# S6E1C1xC register map
Vendor: Cypress; File version: 2.1
CPU: CM0PLUS r0p1, little endian, no MPU, no FPU, 2 interrupt priority bits
Registers are 32-bit, read-write, reset 0x0 unless marked. A register's access mark holds for its fields unless they carry their own. Offsets are from the block's base; [hi:lo] are bit positions; {n}, {i} and the like mark numbered series.

## I2CSLAVE — I2C Slave Wakeup
Base 0x40037980
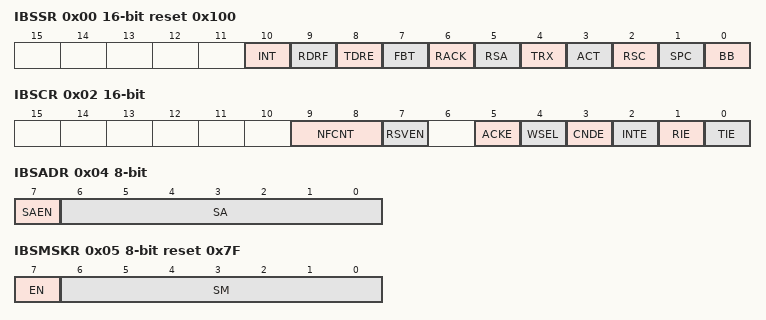
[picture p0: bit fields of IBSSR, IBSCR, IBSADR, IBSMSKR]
0x00 IBSSR 16-bit ro reset 0x100 — I2C Bus Slave Status Register [BHW]
  [10] INT — Status Interrupt Request flag
  [9] RDRF — Reception Interrupt Request flag
  [8] TDRE — Transmission Data Empty flag
  [7] FBT — First Byte flag
  [6] RACK — Acknowledge flag
  [5] RSA — Reserved Address Detection flag
  [4] TRX — Data Direction flag
  [3] ACT — Active flag
  [2] RSC — Re-Start Condition Detection flag
  [1] SPC — Stop Condition Detection flag
  [0] BB — Bus Busy flag
0x02 IBSCR 16-bit — I2C Bus Slave Control Register [BHW]
  [9:8] NFCNT — Noise Filter Control bits
  [7] RSVEN — Reserved Address Enable bit
  [5] ACKE — Acknowledge Enable bit
  [4] WSEL — Wait Select bit
  [3] CNDE — Condition Detection Interrupt Request Enable bit
  [2] INTE — Status Interrupt Request Enable bit
  [1] RIE — Reception Interrupt Request Enable bit
  [0] TIE — Transmission Interrupt Request Enable bit
0x04 IBSADR 8-bit — I2C Bus 7-bit Slave Address Register [BHW]
  [7] SAEN — Slave Address Enable bit
  [6:0] SA — Slave Address Value bit
0x05 IBSMSKR 8-bit reset 0x7F — I2C Bus 7-bit Slave Address Mask Register [BHW]
  [7] EN — Operating Enable bit
  [6:0] SM — Slave Address Mask bit
0x06 IBSDSTUPR 8-bit reset 0xFF — I2C Bus Slave Data Setup Register [BHW]
  [7:0] SETUP — Setup bits
0x08 IBSTDR 8-bit reset 0xFF — I2C Bus Slave Transmission Data Register [BHW]
  [7:0] TDR — Transmission Data bits
0x0C IBSRDR 8-bit ro reset 0xFF — I2C Bus Slave Reception Data Register [BHW]
  [7:0] RDR — Reception Data bis
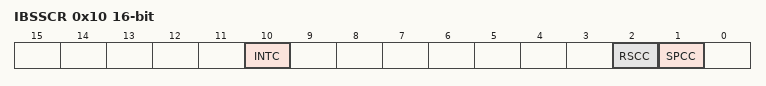
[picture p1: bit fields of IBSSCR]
0x10 IBSSCR 16-bit wo — I2C Bus Slave Status Clear Register [BHW]
  [10] INTC — Status Interrupt Request Flag Clear bit
  [2] RSCC — Re-Start Condition Detection Flag Clear bit
  [1] SPCC — Stop Condition Detection Flag Clear bit
0x14 IBSSSR 16-bit wo — I2C Bus Slave Status Set Register [BHW]
  [8] TDRES — Transmission Data Empty Flag Set bit

## CRC — CRC Registers
Base 0x40039000
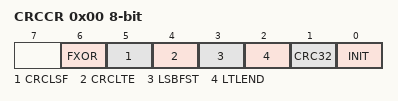
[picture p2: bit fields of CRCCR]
0x00 CRCCR 8-bit — CRC Control Register [BHW]
  [6] FXOR — Final XOR control bit
  [5] CRCLSF — CRC result bit-order setting bit
  [4] CRCLTE — CRC result byte-order setting bit
  [3] LSBFST — Bit-order setting bit
  [2] LTLEND — Byte-order setting bit
  [1] CRC32 — CRC mode selection bit
  [0] INIT — Initialization bit
0x04 CRCINIT reset 0xFFFFFFFF — Initial Value Register [BHW]
  [31:0] D — Initial value bits
0x08 CRCIN — Input Data Register [BHW]
  [31:0] D — Input data bits
0x0C CRCR ro reset 0xFFFFFFFF — CRC Register [BHW]
  [31:0] D — CRC bits

## WC — Watch Counter
Base 0x4003A000
0x00 WCRD 8-bit ro — Watch Counter Read Register [BHW]
  [5:0] CTR — Counter read bits
0x01 WCRL 8-bit — Watch Counter Reload Register [BHW]
  [5:0] RLC — Counter reload value setting bits
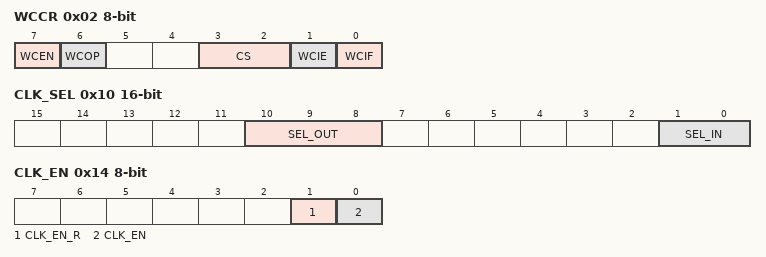
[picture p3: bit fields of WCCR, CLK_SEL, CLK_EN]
0x02 WCCR 8-bit — Watch Counter Control Register [BHW]
  [7] WCEN — Watch counter operation enable bit
  [6] WCOP ro — Watch counter operating state flag
  [3:2] CS — Count clock select bits
  [1] WCIE — Interrupt request enable bit
  [0] WCIF — Interrupt request flag bit
0x10 CLK_SEL 16-bit — Clock Selection Register [BHW]
  [10:8] SEL_OUT — Output clock selection bit
  [1:0] SEL_IN — Input clock selection bit
0x14 CLK_EN 8-bit — Division Clock Enable Register [BHW]
  [1] CLK_EN_R — Division clock enable read bit
  [0] CLK_EN — Division clock enable bit

## LSCRP — Low-speed CR Prescaler Register
Base 0x4003C000
0x00 LCR_PRSLD 8-bit — Low-speed CR Prescaler Control Register [BHW]
  [5:0] LCR_PRSLD — Low-speed CR Prescaler Load

## MFSI2S0 — I2S0 Registers
Base 0x4003CA00
Same registers: MFSI2S1 0x4003CA80
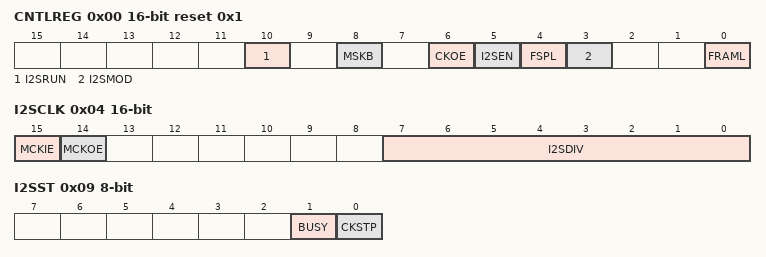
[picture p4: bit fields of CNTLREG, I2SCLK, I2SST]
0x00 CNTLREG 16-bit reset 0x1 — Control Register [HW]
  [10] I2SRUN — I2S clock generate enable bit
  [8] MSKB — Mask bit output bit
  [6] CKOE — I2SCK and I2SWS output enable bit
  [5] I2SEN — I2S mode enable bit
  [4] FSPL — I2SWS polarity set bit
  [3] I2SMOD — I2S mode select bit
  [0] FRAML — Frame length select bit
0x04 I2SCLK 16-bit — I2S Clock Register [HW]
  [15] MCKIE — Main clock input enable bit
  [14] MCKOE — Main clock output enable bit
  [7:0] I2SDIV — I2S clock division set bit
0x08 I2SRST 8-bit wo — I2S Reset Register [B]
  [7:0] I2SRST — I2S software reset bit
0x09 I2SST 8-bit ro — I2S Status Register [B]
  [1] BUSY — Bus busy indication for transmit bit
  [0] CKSTP — Clock stop indication bit

## DSTC — DSTC registers
Base 0x40061000
0x00 DESTP — Descriptor top address Register [BHW]
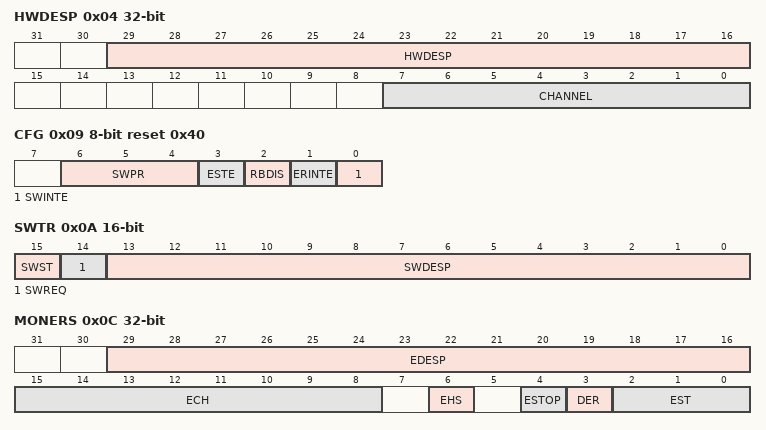
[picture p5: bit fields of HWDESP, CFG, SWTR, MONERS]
0x04 HWDESP — Hardware DES pointer Register [BHW]
  [29:16] HWDESP, [7:0] CHANNEL
0x08 CMD 8-bit reset 0x1 — Command Register [B]
0x09 CFG 8-bit reset 0x40 — Configuration Register [B]
  [6:4] SWPR — Software transfer priority
  [3] ESTE — Error stop enable
  [2] RBDIS — Read skip buffer disable
  [1] ERINTE — Error interrupt enable
  [0] SWINTE — Software interrupt enable
0x0A SWTR 16-bit — Software trigger Register [H]
  [15] SWST ro — Software status
  [14] SWREQ ro — Software request
  [13:0] SWDESP — Software DES pointer
0x0C MONERS — Transfer Error Status Monitor Register [BHW]
  [29:16] EDESP ro — Error DES pointer
  [15:8] ECH ro — Error hardware channel
  [6] EHS ro — Error hardware software
  [4] ESTOP ro — Error stop
  [3] DER ro — Double error
  [2:0] EST ro — Error status
0x10 DREQENB0 — DMA request enable Register 0 [BHW]
0x14 DREQENB1 — DMA request enable Register 1 [BHW]
0x30 HWINT0 — Hardware transfer interrupt Register 0 [BHW]
0x34 HWINT1 — Hardware transfer interrupt Register 1 [BHW]
0x50 HWINTCLR0 — Hardware transfer interrupt clear Register 0 [BHW]
0x54 HWINTCLR1 — Hardware transfer interrupt clear Register 1 [BHW]
0x70 DQMSK0 — DMA request mask Register 0 [BHW]
0x74 DQMSK1 — DMA request mask Register 1 [BHW]
0x90 DQMSKCLR0 — DMA request mask clear Register 0 [BHW]
0x94 DQMSKCLR1 — DMA request mask clear Register 1 [BHW]

## MTB_DWT — Micro Trace Buffer Data Watchpoint and Trace Registers
Base 0xF0001000
0x00 CMP_ADDR_START — MTB_DWT Address Compare Start trace Register [BHW]
  [31:0] ADCMP_STA — MTB_DWT address comparison start trace bits
0x04 CMP_DATA_START — MTB_DWT Data Compare Start trace Register [BHW]
  [31:0] DTCMP_STA — MTB_DWT data comparison start trace bits
0x08 CMP_MASK_START — MTB_DWT Mask Data Compare Start Trace Register [BHW]
  [31:0] MSK_STA — MTB_DWT data compare start trace register mask bits
0x10 CMP_ADDR_STOP — MTB_DWT Address Compare Stop trace Register [BHW]
  [31:0] ADCMP_STO — MTB_DWT address comparison stop trace bits
0x14 CMP_DATA_STOP — MTB_DWT Data Compare Stop trace Register [BHW]
  [31:0] DTCMP_STO — MTB_DWT data comparison stop trace bits
0x18 CMP_MASK_STOP — MTB_DWT Mask Data Compare Stop Trace Register [BHW]
  [31:0] MSK_STO — MTB_DWT data compare stop trace register mask bits
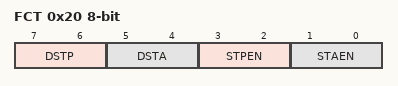
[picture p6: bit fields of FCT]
0x20 FCT 8-bit — MTB_DWT Function Register [BHW]
  [7:6] DSTP — Data size stop bits
  [5:4] DSTA — Data size start bits
  [3:2] STPEN — Enable MTB_DWT stop MTB function bits
  [1:0] STAEN — Enable MTB_DWT start MTB function bits
{0xFC0+4i} PID{i} ro (i=4..7) — Peripheral ID{i} Register [BHW]
  [31:0] PERID — Peripheral ID bits
0xFE0 PID0 ro reset 0x16 — Peripheral ID0 Register [BHW]
  [31:0] PERID — Peripheral ID bits
0xFE4 PID1 ro reset 0x48 — Peripheral ID1 Register [BHW]
  [31:0] PERID — Peripheral ID bits
0xFE8 PID2 ro reset 0x8 — Peripheral ID2 Register [BHW]
  [31:0] PERID — Peripheral ID bits
0xFEC PID3 ro — Peripheral ID3 Register [BHW]
  [31:0] PERID — Peripheral ID bits
0xFF0 CID0 ro reset 0xD — Component ID0 Register [BHW]
  [31:0] CPNTID — Component ID bits
0xFF4 CID1 ro reset 0x90 — Component ID1 Register [BHW]
  [31:0] CPNTID — Component ID bits
0xFF8 CID2 ro reset 0x5 — Component ID2 Register [BHW]
  [31:0] CPNTID — Component ID bits
0xFFC CID3 ro reset 0xB1 — Component ID3 Register [BHW]
  [31:0] CPNTID — Component ID bits

## VIR — Vector Indicate Registers
Base 0xF8000100
{0x0+4i} VIR{i:02} ro (i=0..31) — Vector Indicate Register {i:02} [W]

## Notices in the file
Copyright (C) 2013-2016, Cypress Semiconductor Corporation or a
subsidiary of Cypress Semiconductor Corporation.  All rights reserved.
This software, including source code, documentation and related
materials ("Software"), is owned by Cypress Semiconductor Corporation or
one of its subsidiaries ("Cypress") and is protected by and subject to
worldwide patent protection (United States and foreign), United States
copyright laws and international treaty provisions. Therefore, you may use
this Software only as provided in the license agreement accompanying the
software package from which you obtained this Software ("EULA").
If no EULA applies, Cypress hereby grants you a personal, non-exclusive,
non-transferable license to copy, modify, and compile the
Software source code solely for use in connection with Cypress's
integrated circuit products.  Any reproduction, modification, translation,
compilation, or representation of this Software except as specified
above is prohibited without the express written permission of Cypress.
Disclaimer: THIS SOFTWARE IS PROVIDED AS-IS, WITH NO
WARRANTY OF ANY KIND, EXPRESS OR IMPLIED, INCLUDING,
BUT NOT LIMITED TO, NONINFRINGEMENT, IMPLIED
WARRANTIES OF MERCHANTABILITY AND FITNESS FOR A
PARTICULAR PURPOSE. Cypress reserves the right to make
changes to the Software without notice. Cypress does not assume any
liability arising out of the application or use of the Software or any
product or circuit described in the Software. Cypress does not
authorize its products for use in any products where a malfunction or
failure of the Cypress product may reasonably be expected to result in
significant property damage, injury or death ("High Risk Product"). By
including Cypress's product in a High Risk Product, the manufacturer
of such system or application assumes all risk of such use and in doing
so agrees to indemnify Cypress against all liability.
